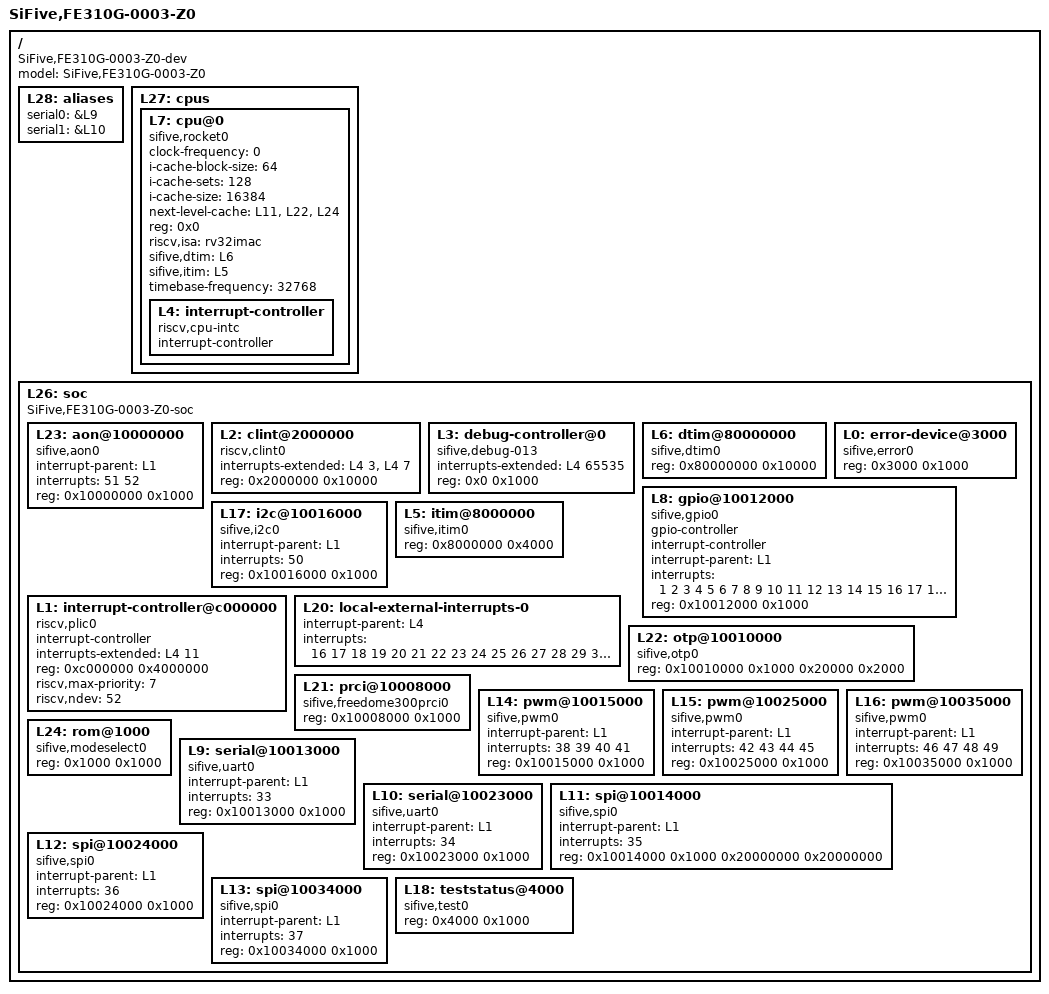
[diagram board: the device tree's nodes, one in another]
/dts-v1/;

/ {
	#address-cells = <1>;
	#size-cells = <1>;
	compatible = "SiFive,FE310G-0003-Z0-dev", "fe310-dev", "sifive-dev";
	model = "SiFive,FE310G-0003-Z0";
	L28: aliases {
		serial0 = &L9;
		serial1 = &L10;
	};
	L27: cpus {
		#address-cells = <1>;
		#size-cells = <0>;
		L7: cpu@0 {
			clock-frequency = <0>;
			compatible = "sifive,rocket0", "riscv";
			device_type = "cpu";
			i-cache-block-size = <64>;
			i-cache-sets = <128>;
			i-cache-size = <16384>;
			next-level-cache = <&L11 &L22 &L24>;
			reg = <0x0>;
			riscv,isa = "rv32imac";
			sifive,dtim = <&L6>;
			sifive,itim = <&L5>;
			status = "okay";
			timebase-frequency = <32768>;
			L4: interrupt-controller {
				#interrupt-cells = <1>;
				compatible = "riscv,cpu-intc";
				interrupt-controller;
			};
		};
	};
	L26: soc {
		#address-cells = <1>;
		#size-cells = <1>;
		compatible = "SiFive,FE310G-0003-Z0-soc", "fe310-soc", "sifive-soc", "simple-bus";
		ranges;
		L23: aon@10000000 {
			compatible = "sifive,aon0";
			interrupt-parent = <&L1>;
			interrupts = <51 52>;
			reg = <0x10000000 0x1000>;
			reg-names = "control";
		};
		L2: clint@2000000 {
			compatible = "riscv,clint0";
			interrupts-extended = <&L4 3 &L4 7>;
			reg = <0x2000000 0x10000>;
			reg-names = "control";
		};
		L3: debug-controller@0 {
			compatible = "sifive,debug-013", "riscv,debug-013";
			interrupts-extended = <&L4 65535>;
			reg = <0x0 0x1000>;
			reg-names = "control";
		};
		L6: dtim@80000000 {
			compatible = "sifive,dtim0";
			reg = <0x80000000 0x10000>;
			reg-names = "mem";
		};
		L0: error-device@3000 {
			compatible = "sifive,error0";
			reg = <0x3000 0x1000>;
		};
		L8: gpio@10012000 {
			#gpio-cells = <2>;
			#interrupt-cells = <2>;
			compatible = "sifive,gpio0", "sifive,gpio1";
			gpio-controller;
			interrupt-controller;
			interrupt-parent = <&L1>;
			interrupts = <1 2 3 4 5 6 7 8 9 10 11 12 13 14 15 16 17 18 19 20 21 22 23 24 25 26 27 28 29 30 31 32>;
			reg = <0x10012000 0x1000>;
			reg-names = "control";
		};
		L17: i2c@10016000 {
			compatible = "sifive,i2c0";
			interrupt-parent = <&L1>;
			interrupts = <50>;
			reg = <0x10016000 0x1000>;
			reg-names = "control";
		};
		L1: interrupt-controller@c000000 {
			#interrupt-cells = <1>;
			compatible = "riscv,plic0";
			interrupt-controller;
			interrupts-extended = <&L4 11>;
			reg = <0xc000000 0x4000000>;
			reg-names = "control";
			riscv,max-priority = <7>;
			riscv,ndev = <52>;
		};
		L5: itim@8000000 {
			compatible = "sifive,itim0";
			reg = <0x8000000 0x4000>;
			reg-names = "mem";
		};
		L20: local-external-interrupts-0 {
			interrupt-parent = <&L4>;
			interrupts = <16 17 18 19 20 21 22 23 24 25 26 27 28 29 30 31>;
		};
		L22: otp@10010000 {
			compatible = "sifive,otp0";
			reg = <0x10010000 0x1000 0x20000 0x2000>;
			reg-names = "control", "mem";
		};
		L21: prci@10008000 {
			compatible = "sifive,freedome300prci0";
			reg = <0x10008000 0x1000>;
			reg-names = "control";
		};
		L14: pwm@10015000 {
			compatible = "sifive,pwm0";
			interrupt-parent = <&L1>;
			interrupts = <38 39 40 41>;
			reg = <0x10015000 0x1000>;
			reg-names = "control";
		};
		L15: pwm@10025000 {
			compatible = "sifive,pwm0";
			interrupt-parent = <&L1>;
			interrupts = <42 43 44 45>;
			reg = <0x10025000 0x1000>;
			reg-names = "control";
		};
		L16: pwm@10035000 {
			compatible = "sifive,pwm0";
			interrupt-parent = <&L1>;
			interrupts = <46 47 48 49>;
			reg = <0x10035000 0x1000>;
			reg-names = "control";
		};
		L24: rom@1000 {
			compatible = "sifive,modeselect0";
			reg = <0x1000 0x1000>;
			reg-names = "mem";
		};
		L9: serial@10013000 {
			compatible = "sifive,uart0";
			interrupt-parent = <&L1>;
			interrupts = <33>;
			reg = <0x10013000 0x1000>;
			reg-names = "control";
		};
		L10: serial@10023000 {
			compatible = "sifive,uart0";
			interrupt-parent = <&L1>;
			interrupts = <34>;
			reg = <0x10023000 0x1000>;
			reg-names = "control";
		};
		L11: spi@10014000 {
			#address-cells = <1>;
			#size-cells = <0>;
			compatible = "sifive,spi0";
			interrupt-parent = <&L1>;
			interrupts = <35>;
			reg = <0x10014000 0x1000 0x20000000 0x20000000>;
			reg-names = "control", "mem";
		};
		L12: spi@10024000 {
			#address-cells = <1>;
			#size-cells = <0>;
			compatible = "sifive,spi0";
			interrupt-parent = <&L1>;
			interrupts = <36>;
			reg = <0x10024000 0x1000>;
			reg-names = "control";
		};
		L13: spi@10034000 {
			#address-cells = <1>;
			#size-cells = <0>;
			compatible = "sifive,spi0";
			interrupt-parent = <&L1>;
			interrupts = <37>;
			reg = <0x10034000 0x1000>;
			reg-names = "control";
		};
		L18: teststatus@4000 {
			compatible = "sifive,test0";
			reg = <0x4000 0x1000>;
			reg-names = "control";
		};
	};
};
